# ATL0_REG register map
Vendor: Texas Instruments
Peripheral module from a debugger description file (folder J7VCL).
Registers are 32-bit, read-write, reset 0x0 unless marked. A register's access mark holds for its fields unless they carry their own. Offsets are as the file gives them; lines under a group give offsets from that group; [hi:lo] are bit positions; {n}, {i} and the like mark numbered series; 'fields as' and 'values as' point back to an identical list; <NAME> marks a mode.

## ATL0_REG
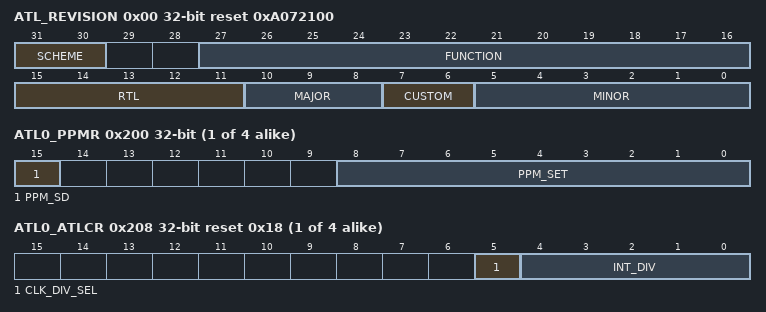
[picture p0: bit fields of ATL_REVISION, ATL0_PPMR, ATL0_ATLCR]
0x00 ATL_REVISION ro reset 0xA072100 — Return to the . The Revision Register contains the major and minor revisions for the module.
  [31:30] SCHEME — PID register scheme
  [27:16] FUNCTION — Module ID
  [15:11] RTL
  [10:8] MAJOR
  [7:6] CUSTOM
  [5:0] MINOR
{0x200+0x80*i} ATL{i}_PPMR (i=0..3) — Return to the . The PPM register is used by the Audio re-timing code. The DAC over-sampling clock will slow down or speed up by the PPM written to bits [8:0].
  [15] PPM_SD
  [8:0] PPM_SET — This is the
{0x204+0x80*i} ATL{i}_BBSR ro (i=0..3) — Return to the . The measuring circuit produces a 16-bit Sample Count. Its inputs are the Audio IIS Word Select (AWS) and the Baseband IIS Word Select (BWS) from their respective MCASP pins. The sample count is a read-only register.
  [15:0] SMP_CNT — This is the
{0x208+0x80*i} ATL{i}_ATLCR reset 0x18 (i=0..3) — Return to the . The modem Clock Divide Select bit is used during factory calibration of the radio to match latency between the analog and digital signal paths. The ATL Internal Divider divides down the ATL master clock to make ATCLK.
  [5] CLK_DIV_SEL
  [4:0] INT_DIV — Sets ratio of ATLPCLK to ATCLK
{0x210+0x80*i} ATL{i}_SWEN (i=0..3) — Return to the . The software enable register is used to enable/disable the ATL.
  [0] ENABLE — When disabled the ATL registers are forced to known states for simulation purposes.
{0x214+0x80*i} ATL{i}_BWSMUX (i=0..3) — Return to the . The Baseband IIS Word Select mux select control register
  [3:0] SELECT — BWS input select:
{0x218+0x80*i} ATL{i}_AWSMUX (i=0..3) — Return to the . The Audio IIS Word Select mux select control register
  [3:0] SELECT — AWS input select:
0x21C ATL0_PCLKMUX — Return to the . ATL core input clock mux select control register
  [0] SELECT — ATL
{0x21C+0x80*i} ATL{i}_PCLKMUX (i=1..3) — Return to the . ATL core input clock mux select control register
  [0] SELECT — Non-functional
